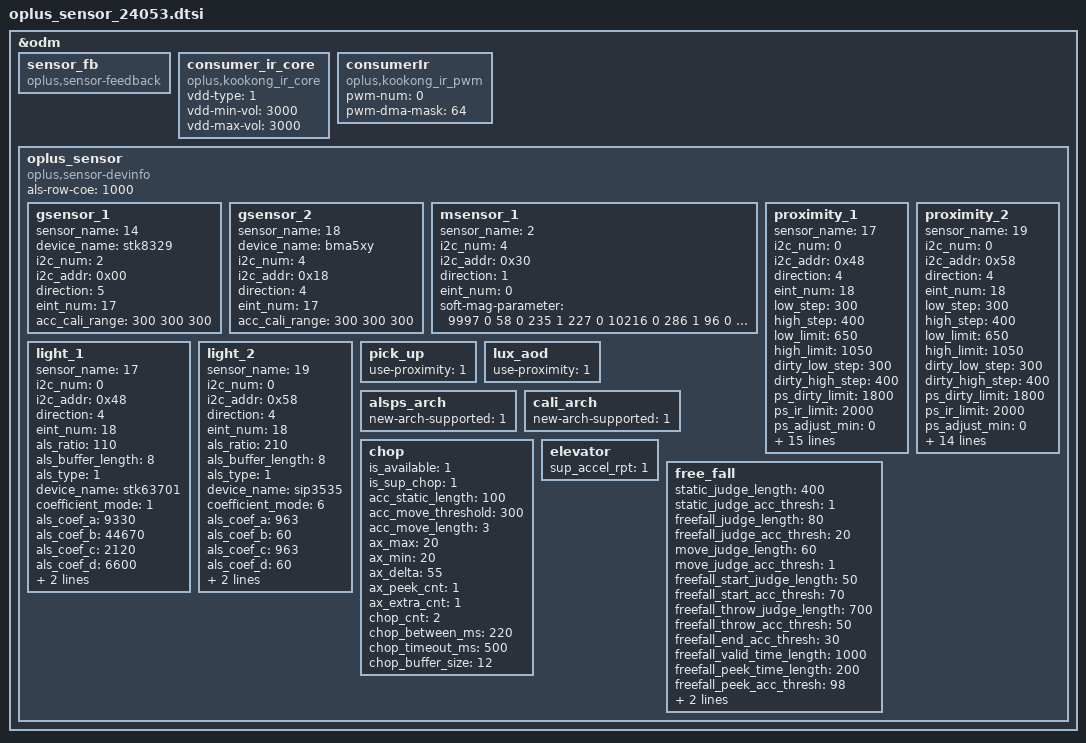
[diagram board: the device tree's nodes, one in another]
&odm {
	sensor_fb: sensor_fb {
		compatible = "oplus,sensor-feedback";
	};
	consumer_ir_core: consumer_ir_core {
		compatible = "oplus,kookong_ir_core";
		status = "okay";
		//vdd-supply = <&mt6373_vmch_eint_high>;
		vdd-type = <1>;
		vdd-min-vol = <3000>;
		vdd-max-vol = <3000>;
	};
	consumerIr: consumerIr {
		compatible = "oplus,kookong_ir_pwm";
		status = "okay";
		pwm-num = <0>;
		pwm-dma-mask = <64>;
	};
	oplus_sensor:oplus_sensor {
		compatible = "oplus,sensor-devinfo";
		als-row-coe = <1000>;
		/* sensor start */
		/*
		enum {
			LIS3DH,
			LSM6DS3,
			BMI160,
			LIS2HH12,
			LSM6DSM,
			BMI2XY,
			LSM6DSO,
			ICM4X6XX,
			ICM4263X,
			ICM4N607,
			BMI22X,
			SC7A20,
			MC34X9,
			BMA4XY,
			STK8329,
			BMI3XY,
			ICM456XY,
			SC7I22,
			BMA5XY,
		};
		*/
		gsensor_1: gsensor_1 {
			status = "okay";
			sensor_name = <14>;//STK8329
			device_name = "stk8329";
			i2c_num = <2>;
			i2c_addr = <0x00>;
			direction = <5>;
			eint_num = <17>;
			acc_cali_range= <300 300 300>;
		};
		gsensor_2: gsensor_2 {
			status = "okay";
			sensor_name = <18>;//BMA5XY
			device_name = "bma5xy";
			i2c_num = <4>;
			i2c_addr = <0x18>;
			direction = <4>;
			eint_num = <17>;
			acc_cali_range= <300 300 300>;
		};
		/*
		enum {
			AKM09911,
			MMC3530,
			MMC5603,
			MXG4300,
			AKM09918,
		};
		*/
		msensor_1: msensor_1 {
			status = "okay";
			sensor_name = <2>;//MMC5603
			i2c_num = <4>;
			i2c_addr = <0x30>;
			direction = <1>;
			eint_num = <0>;
			soft-mag-parameter = <9997 0 58 0 235 1 227 0 10216 0 286 1 96 0 497 0 9945 0>;
		};
		/*
		enum {
			TMD2725,
			APSD9922,
			STK3335,
			STK3331,
			STK2232,
			TCS3701,
			STK32600,
			STK33502,
			MN78911,
			TCS3720,
			SIP3515,
			STK3329,
			LTR569,
			SIP3510,
			SIP3625,
			STK33C01,
			SIP3535,
			STK63701,
			TMD2765,
			SIP3511,
		};
		*/
		proximity_1: proximity_1 {
			status = "okay";
			sensor_name = <17>; //stk63701
			i2c_num = <0>;
			i2c_addr = <0x48>;
			direction = <4>;
			eint_num = <18>;
			low_step = <300>;
			high_step = <400>;
			low_limit = <650>;
			high_limit = <1050>;
			dirty_low_step = <300>;
			dirty_high_step = <400>;
			ps_dirty_limit = <1800>;
			ps_ir_limit = <2000>;
			ps_adjust_min = <0>;
			ps_adjust_max = <1850>;
			sampling_count = <5>;
			step_max = <400>;
			step_min = <100>;
			step_div = <2000>;
			anti_shake_delta = <70>;
			dynamic_cali_max = <2000>;
			raw2offset_radio = <1000>;
			offset_max = <60000>;
			offset_range_min = <0>;
			offset_range_max = <65534>;
			force_cali_limit = <2000>;
			cali_jitter_limit = <20>;
			cal_offset_margin = <3000>;
			sensor-reg = <0x05 0x20 0x03 0x2C>;
		};
		proximity_2: proximity_2 {
			status = "okay";
			sensor_name = <19>; //SIP3511
			i2c_num = <0>;
			i2c_addr = <0x58>;
			direction = <4>;
			eint_num = <18>;
			low_step = <300>;
			high_step = <400>;
			low_limit = <650>;
			high_limit = <1050>;
			dirty_low_step = <300>;
			dirty_high_step = <400>;
			ps_dirty_limit = <1800>;
			ps_ir_limit = <2000>;
			ps_adjust_min = <0>;
			ps_adjust_max = <1850>;
			sampling_count = <5>;
			step_max = <400>;
			step_min = <100>;
			step_div = <2000>;
			anti_shake_delta = <70>;
			dynamic_cali_max = <2000>;
			raw2offset_radio = <1000>;
			offset_max = <60000>;
			offset_range_min = <0>;
			offset_range_max = <65534>;
			force_cali_limit = <2000>;
			cali_jitter_limit = <20>;
			cal_offset_margin = <3000>;
		};
		light_1: light_1 {
			status = "okay";
			sensor_name = <17>; //stk63701
			i2c_num = <0>;
			i2c_addr = <0x48>;
			direction = <4>;
			eint_num = <18>;
			als_ratio = <110>;
			als_buffer_length =<8>;
			als_type = <1>;//<1-normal;2-under screen;3-normal needed compensation>
			device_name = "stk63701";
			coefficient_mode = <1>;
			als_coef_a = <9330>; //*100
			als_coef_b = <44670>; //*100
			als_coef_c = <2120>; //*100
			als_coef_d = <6600>; //*100
			als_coef_e = <9000>; //*100
			als_coef_ratio = <50>;
		};
		light_2: light_2 {
			status = "okay";
			sensor_name = <19>; //SIP3511
			i2c_num = <0>;
			i2c_addr = <0x58>;
			direction = <4>;
			eint_num = <18>;
			als_ratio = <210>;
			als_buffer_length =<8>;
			als_type = <1>;//<1-normal;2-under screen;3-normal needed compensation>
			device_name = "sip3535";
			coefficient_mode = <6>;
			als_coef_a = <963>; //*100
			als_coef_b = <60>; //*100
			als_coef_c = <963>; //*100
			als_coef_d = <60>; //*100
			als_coef_e = <2490>; //*100
			als_coef_ratio = <1500>;
		};
		pick_up: pick_up {
			status = "okay";
			use-proximity = <1>;
		};
		lux_aod: lux_aod {
			status = "okay";
			use-proximity = <1>;
		};
		alsps_arch: alsps_arch {
			status = "okay";
			new-arch-supported = <1>;
		};
		cali_arch: cali_arch {
			status = "okay";
			new-arch-supported = <1>;
		};
		chop: chop {
			status = "okay";
			is_available = <1>;
			is_sup_chop = <1>;

			acc_static_length = <100>;
			acc_move_threshold = <300>;
			acc_move_length = <3>;
			ax_max = <20>;
			ax_min = <20>;
			ax_delta = <55>;
			ax_peek_cnt = <1>;
			ax_extra_cnt = <1>;
			chop_cnt = <2>;
			chop_between_ms = <220>;
			chop_timeout_ms = <500>;
			chop_buffer_size = <12>;
		};
		elevator: elevator{
			status = "okay";
			sup_accel_rpt = <1>;
		};
		free_fall: free_fall{
			status = "okay";
			static_judge_length = <400>;
			static_judge_acc_thresh = <1>;
			freefall_judge_length = <80>;
			freefall_judge_acc_thresh = <20>;
			move_judge_length = <60>;
			move_judge_acc_thresh = <1>;
			freefall_start_judge_length  = <50>;
			freefall_start_acc_thresh = <70>;
			freefall_throw_judge_length = <700>;
			freefall_throw_acc_thresh = <50>;
			freefall_end_acc_thresh = <30>;
			freefall_valid_time_length = <1000>;
			freefall_peek_time_length = <200>;
			freefall_peek_acc_thresh = <98>;
			freefall_material_thresh = <900>;
			valid_peek_interval_thresh = <10000>;
		};
	};
/* sensor end */
};
